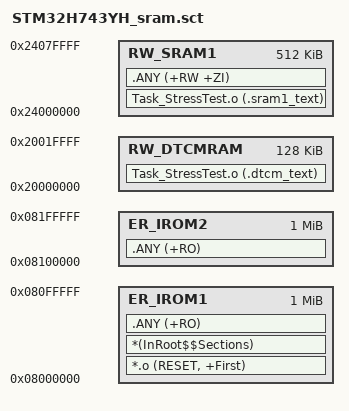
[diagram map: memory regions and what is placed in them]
; *************************************************************
; *** Scatter-Loading Description File generated by uVision ***
; *************************************************************

;LR_IROM1 0x08000000 0x00100000  {    ; load region size_region
;  ER_IROM1 0x08000000 0x00100000  {  ; load address = execution address
;   *.o (RESET, +First)
;   *(InRoot$$Sections)
;   .ANY (+RO)
;   .ANY (+XO)
;  }
;  RW_IRAM1 0x20000000 0x00020000  {  ; RW data
;   .ANY (+RW +ZI)
;  }
;  RW_IRAM2 0x24000000 0x00080000  {
;   .ANY (+RW +ZI)
;  }
;;  ; --- 新增：堆区域 (占据 AXI SRAM 剩余的 128KB) ---
;;  ARM_LIB_HEAP 0x24060000 EMPTY 0x00020000 {
;;  }

;;  ; --- 新增：栈区域 (通常放在 DTCM 顶部，如果你想手动指定) ---
;;  ARM_LIB_STACK 0x20020000 EMPTY -0x00002000 {
;;  }
;}

;LR_IROM2 0x08100000 0x00100000  {
;  ER_IROM2 0x08100000 0x00100000  {  ; load address = execution address
;   .ANY (+RO)
;  }
;}
; *************************************************************


; STM32H743 分散加载文件：支持DTCM和SRAM1代码段
; 内存映射：
; FLASH: 0x08000000 - 0x081FFFFF (2MB)
; DTCM:  0x20000000 - 0x2001FFFF (128KB)
; SRAM1: 0x24000000 - 0x2407FFFF (512KB)
; SRAM2: 0x30000000 - 0x3003FFFF (256KB)

LR_IROM1 0x08000000 0x00100000  {    ; 加载域：FLASH (2MB)
  ER_IROM1 0x08000000 0x00100000  {    ; 执行域：FLASH
    *.o (RESET, +First)
    *(InRoot$$Sections)
    .ANY (+RO)
  }

  RW_DTCMRAM 0x20000000 0x00020000  {  ; 执行域：DTCM RAM (128KB)
    Task_StressTest.o (.dtcm_text)              ; 自定义DTCM代码段（只读）

  }

  RW_SRAM1 0x24000000 0x00080000  {    ; 执行域：SRAM1 (512KB)
    Task_StressTest.o (.sram1_text)             ; 自定义SRAM1代码段（只读）
	   .ANY (+RW +ZI)                  ; 所有默认数据优先放SRAM1（512KB足够）
  }

;  RW_SRAM2 0x24080000 0x00080000  {    ; 执行域：SRAM2 (256KB)
;    .ANY (+RW +ZI +RO)                     ; 其他数据默认放SRAM2
;  }
}
LR_IROM2 0x08100000 0x00100000  {
  ER_IROM2 0x08100000 0x00100000  {  ; load address = execution address
   .ANY (+RO)
  }
}












